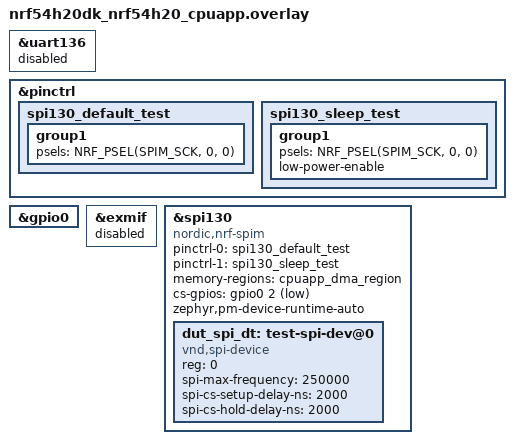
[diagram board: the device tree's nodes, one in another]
/*
 * Copyright (c) 2026 Nordic Semiconductor ASA
 *
 * SPDX-License-Identifier: LicenseRef-Nordic-5-Clause
 */

/* Test requires wire connections between SPIM pins driven by the application
 * core and GPIO inputs monitored by the FLPR core:
 *  - SPIM SCK P0.0 - P0.1,
 *  - SPIM CS  P0.2 - P0.4.
 */

/* Console of the FLPR core. */
&uart136 {
	status = "reserved";
};

&pinctrl {
	spi130_default_test: spi130_default_test {
		group1 {
			psels = <NRF_PSEL(SPIM_SCK, 0, 0)>;
		};
	};

	spi130_sleep_test: spi130_sleep_test {
		group1 {
			psels = <NRF_PSEL(SPIM_SCK, 0, 0)>;
			low-power-enable;
		};
	};
};

&gpio0 {
	status = "okay";
};

&exmif {
	status = "disabled";
};

&spi130 {
	compatible = "nordic,nrf-spim";
	status = "okay";
	pinctrl-0 = <&spi130_default_test>;
	pinctrl-1 = <&spi130_sleep_test>;
	pinctrl-names = "default", "sleep";
	memory-regions = <&cpuapp_dma_region>;
	cs-gpios = <&gpio0 2 GPIO_ACTIVE_LOW>;
	zephyr,pm-device-runtime-auto;

	dut_spi_dt: test-spi-dev@0 {
		compatible = "vnd,spi-device";
		reg = <0>;
		spi-max-frequency = <250000>;
		spi-cs-setup-delay-ns = <2000>;
		spi-cs-hold-delay-ns = <2000>;
	};
};
